# va416xx register map
Vendor: VORAGO TECHNOLOGIES; Series: M4; File version: 1.3
CPU: CM4 r0p1, little endian, no MPU, FPU, 4 interrupt priority bits
Registers are 32-bit, read-write, reset 0x0 unless marked. A register's access mark holds for its fields unless they carry their own. Offsets are from the block's base; [hi:lo] are bit positions; {n}, {i} and the like mark numbered series; 'fields as' and 'values as' point back to an identical list.

## ETH — Ethernet Block
Base 0x40004000
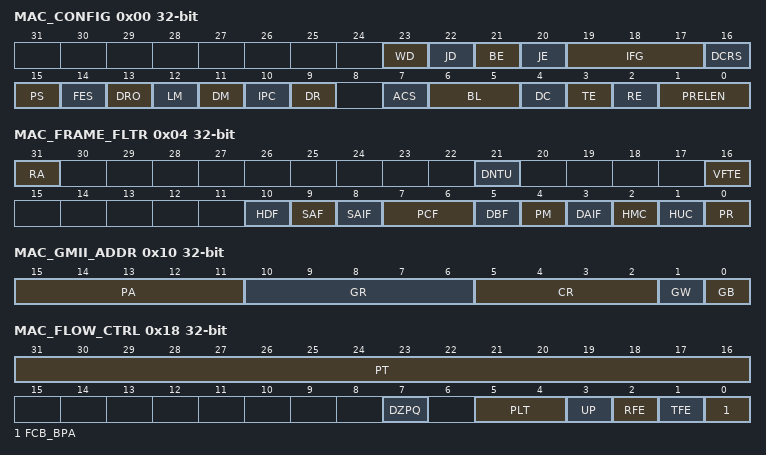
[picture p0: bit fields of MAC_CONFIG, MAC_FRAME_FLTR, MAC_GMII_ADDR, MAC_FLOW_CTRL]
0x00 MAC_CONFIG — Operation mode register for the MAC
  [23] WD — Watchdog disable
  [22] JD — Jabber Disable
  [21] BE — Frame Burst Enable
  [20] JE — Jumbo Frame Enable
  [19:17] IFG — Inter-Frame Gap
  [16] DCRS — Disable Carrier Sense During Transmission
  [15] PS — Port Select
  [14] FES — Speed
  [13] DRO — Disable Receive Own
  [12] LM — Loopback Mode
  [11] DM — Duplex Mode
  [10] IPC — Checksum Offload
  [9] DR — Disable Retry
  [7] ACS — Automatic Pad, or CRC Stripping
  [6:5] BL — Back-Off-Limit
  [4] DC — Deferral Check
  [3] TE — Transmitter Enable
  [2] RE — Receiver Enable
  [1:0] PRELEN — Preamble Length for Transmit frames
0x04 MAC_FRAME_FLTR — Contains the frame filtering controls
  [31] RA — Receive All
  [21] DNTU — Drop non TCP/UDP over IP Frames
  [16] VFTE — VLAN Tag Filter Enable
  [10] HDF — Hash or Perfect Filter
  [9] SAF — Source Address Filter Enable
  [8] SAIF — SA Inverse Filtering
  [7:6] PCF — Pass Control Frames
  [5] DBF — Disable Broadcast Frames
  [4] PM — Pass All Multicast
  [3] DAIF — DA Inverse Filtering
  [2] HMC — Hash Multicast
  [1] HUC — Hash Unicast
  [0] PR — Promiscuous Mode
0x10 MAC_GMII_ADDR — Controls the management cycles to an external PHY
  [15:11] PA — Physical Layer Address
  [10:6] GR — GMII Register
  [5:2] CR — CSR Clock Range
  [1] GW — GMII Write/Read
  [0] GB — GMII Busy
0x14 MAC_GMII_DATA — Contains the data to be written to or read from the PHY register
  [15:0] GD — GMII Data
0x18 MAC_FLOW_CTRL — Controls the generation of control frames
  [31:16] PT — Pause time
  [7] DZPQ — Disable Zero-Quanta Pause
  [5:4] PLT — Pause Low Threshold
  [3] UP — Unicast Pause Frame Detect
  [2] RFE — Receive Flow Control Enable
  [1] TFE — Transmit Flow Control Enable
  [0] FCB_BPA — Flow Control Busy or Backpressure Activate
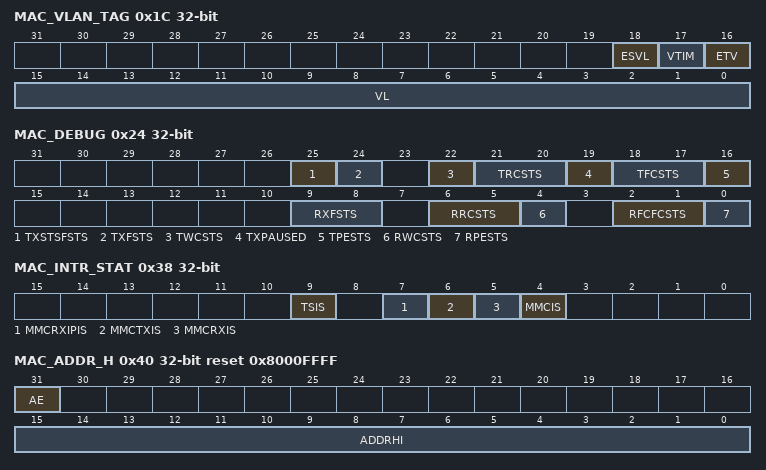
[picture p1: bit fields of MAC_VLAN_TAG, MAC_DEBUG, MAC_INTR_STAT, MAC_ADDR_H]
0x1C MAC_VLAN_TAG — Identifies IEEE 802.1Q VLAN type frames
  [18] ESVL — Enable S-VLAN
  [17] VTIM — VLAN Tag Inverse Match Enable
  [16] ETV — Enable 12-Bit VLAN Tag Comparison
  [15:0] VL — VLAN Tag identifier for Receive Frames
0x24 MAC_DEBUG ro — Gives the status of the various internal blocks for debugging
  [25] TXSTSFSTS — MTL TxStatus FIFO Full Status
  [24] TXFSTS — MTL Tx FIFO Not Empty Status
  [22] TWCSTS — MTL Tx FIFO Write Controller Status
  [21:20] TRCSTS — MTL Tx FIFO Read Controller Status
  [19] TXPAUSED — MAC Transmitter in Pause
  [18:17] TFCSTS — PAC Transmit Frame Controller Status
  [16] TPESTS — MAC GMII or MII Transmit Protocol Engine Status
  [9:8] RXFSTS — MTL RxFIFO Fill-Level Status
  [6:5] RRCSTS — MTL RxFIFO Read Controller State
  [4] RWCSTS — MTL Rx FIFO Write Controller Active Status
  [2:1] RFCFCSTS — MAC Receive Frame FIFO Controller Status
  [0] RPESTS — MAC GMII or MII Receive Protocol Engine Status
0x38 MAC_INTR_STAT ro — Contains the interrupt status
  [9] TSIS — Timestamp Interrupt Status
  [7] MMCRXIPIS — MMC Receive Checksum Offload Interrupt Status
  [6] MMCTXIS — MMC Transmit Interrupt Status
  [5] MMCRXIS — MMC Receive Interrupt Status
  [4] MMCIS — MMC Interrupt Status
0x3C MAC_INTR_MASK — Contains the masks for generating interrupt
  [9] TSIM — Timestamp Interrupt Mask
0x40 MAC_ADDR_H reset 0x8000FFFF — Contains the high 16-bits of the first MAC Address
  [31] AE ro — Address Enable, This bit is always set to 1
  [15:0] ADDRHI ro — MAC Address0[47:32]
0x44 MAC_ADDR_L reset 0xFFFFFFFF — Contains the Low 32-bits of the first MAC Address
  [31:0] ADDRLO ro — MAC Address0[31:0]
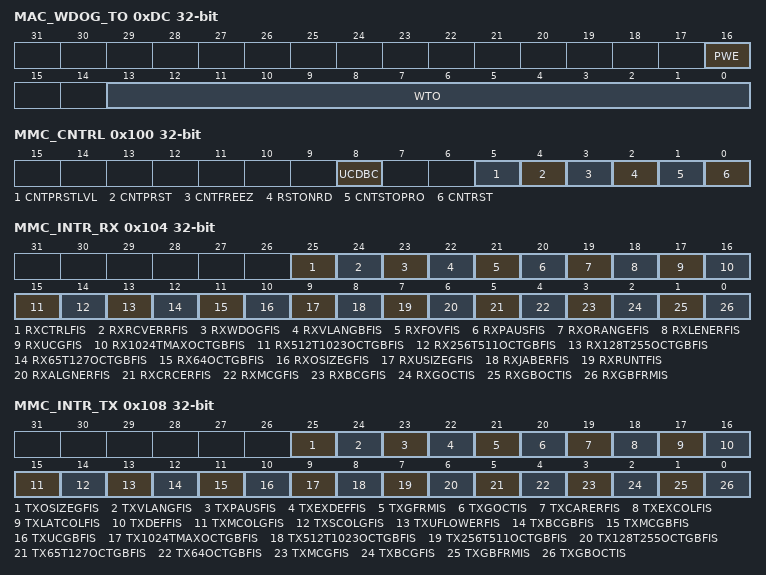
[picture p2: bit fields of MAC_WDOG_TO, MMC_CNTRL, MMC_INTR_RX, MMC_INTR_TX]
0xDC MAC_WDOG_TO — Controls the watchdog time-out for received frames
  [16] PWE — Programmable Watchdog Enable
  [13:0] WTO — Watchdog Timeout
0x100 MMC_CNTRL — MMC Control Register
  [8] UCDBC — Update MMC Counters for Dropped Broadcast Frames
  [5] CNTPRSTLVL — Full-Half Preset
  [4] CNTPRST — Counters Preset
  [3] CNTFREEZ — MMC Counter Freeze
  [2] RSTONRD — Reset on Read
  [1] CNTSTOPRO — Counter Stop Rollover
  [0] CNTRST — Counters Reset
0x104 MMC_INTR_RX — MMC Receive Interrupt Register
  [25] RXCTRLFIS — MMC Receive Control Frame Counter Interrupt Status
  [24] RXRCVERRFIS — MMC Receive Error Frame Counter Interrupt Status
  [23] RXWDOGFIS — MMC Receive Watchdog Error Frame Counter Interrupt Status
  [22] RXVLANGBFIS — MMC Receive VLAN Good Bad Frame Counter Interrupt Status
  [21] RXFOVFIS — MMC Receive FIFO Overflow Frame Counter Interrupt Status
  [20] RXPAUSFIS — MMC Receive Pause Frame Counter Interrupt Status
  [19] RXORANGEFIS — MMC Receive Out Of Range Error Frame Counter Interrupt Status.
  [18] RXLENERFIS — MMC Receive Length Error Frame Counter Interrupt Status
  [17] RXUCGFIS — MMC Receive Unicast Good Frame Counter Interrupt Status
  [16] RX1024TMAXOCTGBFIS — MMC Receive 1024 to Maximum Octet Good Bad Frame Counter Interrupt Status.
  [15] RX512T1023OCTGBFIS — MMC Receive 512 to 1023 Octet Good Bad Frame Counter Interrupt Status
  [14] RX256T511OCTGBFIS — MMC Receive 256 to 511 Octet Good Bad Frame Counter Interrupt Status
  [13] RX128T255OCTGBFIS — MMC Receive 128 to 255 Octet Good Bad Frame Counter Interrupt Status
  [12] RX65T127OCTGBFIS — MMC Receive 65 to 127 Octet Good Bad Frame Counter Interrupt Status
  [11] RX64OCTGBFIS — MMC Receive 64 Octet Good Bad Frame Counter Interrupt Status
  [10] RXOSIZEGFIS — MMC Receive Oversize Good Frame Counter Interrupt Status
  [9] RXUSIZEGFIS — MMC Receive Undersize Good Frame Counter Interrupt Status
  [8] RXJABERFIS — MMC Receive Jabber Error Frame Counter Interrupt Status
  [7] RXRUNTFIS — MMC Receive Runt Frame Counter Interrupt Status
  [6] RXALGNERFIS — MMC Receive Alignment Error Frame Counter Interrupt Status
  [5] RXCRCERFIS — MMC Receive CRC Error Frame Counter Interrupt Status
  [4] RXMCGFIS — MMC Receive Multicast Good Frame Counter Interrupt Status
  [3] RXBCGFIS — MMC Receive Broadcast Good Frame Counter Interrupt Status
  [2] RXGOCTIS — MMC Receive Good Octet Counter Interrupt Status
  [1] RXGBOCTIS — MMC Receive Good Bad Octet Counter Interrupt Status
  [0] RXGBFRMIS — MMC Receive Good Bad Frame Counter Interrupt Status
0x108 MMC_INTR_TX — MMC Transmit Interrupt Register
  [25] TXOSIZEGFIS — MMC Transmit Oversize Good Frame Counter Interrupt Status
  [24] TXVLANGFIS — MMC Transmit VLAN Good Frame Counter Interrupt Status
  [23] TXPAUSFIS — MMC Transmit Pause Frame Counter Interrupt Status
  [22] TXEXDEFFIS — MMC Transmit Excessive Deferral Frame Counter Interrupt Status
  [21] TXGFRMIS — MMC Transmit Good Frame Counter Interrupt Status
  [20] TXGOCTIS — MMC Transmit Good Octet Counter Interrupt Status
  [19] TXCARERFIS — MMC Transmit Carrier Error Frame Counter Interrupt Status
  [18] TXEXCOLFIS — MMC Transmit Excessive Collision Frame Counter Interrupt Status
  [17] TXLATCOLFIS — MMC Transmit Late Collision Frame Counter Interrupt Status
  [16] TXDEFFIS — MMC Transmit Deferred Frame Counter Interrupt Status
  [15] TXMCOLGFIS — MMC Transmit Multiple Collision Good Frame Counter Interrupt Status
  [14] TXSCOLGFIS — MMC Transmit Single Collision Good Frame Counter Interrupt Status
  [13] TXUFLOWERFIS — MMC Transmit Underflow Error Frame Counter Interrupt Status
  [12] TXBCGBFIS — MMC Transmit Broadcast Good Bad Frame Counter Interrupt Status
  [11] TXMCGBFIS — MMC Transmit Multicast Good Bad Frame Counter Interrupt Status
  [10] TXUCGBFIS — MMC Transmit Unicast Good Bad Frame Counter Interrupt Status
  [9] TX1024TMAXOCTGBFIS — MMC Transmit 1024 to Maximum Octet Good Bad Frame Counter
  [8] TX512T1023OCTGBFIS — MMC Transmit 512 to 1023 Octet Good Bad Frame Counter Interrupt Status
  [7] TX256T511OCTGBFIS — MMC Transmit 256 to 511 Octet Good Bad Frame Counter Interrupt Status
  [6] TX128T255OCTGBFIS — MMC Transmit 128 to 255 Octet Good Bad Frame Counter Interrupt Status
  [5] TX65T127OCTGBFIS — MMC Transmit 65 to 127 Octet Good Bad Frame Counter Interrupt Status
  [4] TX64OCTGBFIS — MMC Transmit 64 Octet Good Bad Frame Counter Interrupt Status
  [3] TXMCGFIS — MMC Transmit Multicast Good Frame Counter Interrupt Status
  [2] TXBCGFIS — MMC Transmit Broadcast Good Frame Counter Interrupt Status
  [1] TXGBFRMIS — MMC Transmit Good Bad Frame Counter Interrupt Status
  [0] TXGBOCTIS — MMC Transmit Good Bad Octet Counter Interrupt Status
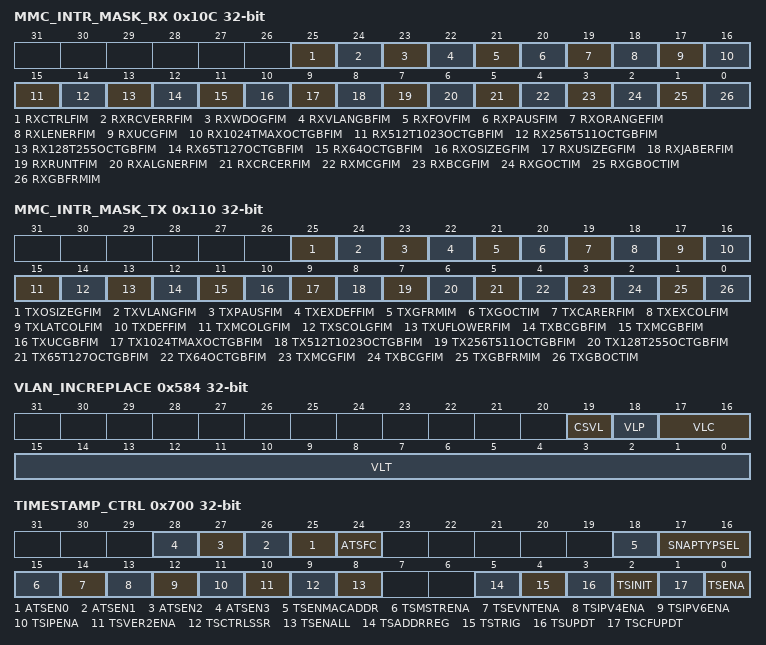
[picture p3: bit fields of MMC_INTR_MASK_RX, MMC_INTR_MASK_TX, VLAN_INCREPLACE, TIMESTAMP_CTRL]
0x10C MMC_INTR_MASK_RX — MMC Receive Interrupt Mask Register
  [25] RXCTRLFIM — MMC Receive Control Frame Counter Interrupt Mask
  [24] RXRCVERRFIM — MMC Receive Error Frame Counter Interrupt Mask
  [23] RXWDOGFIM — MMC Receive Watchdog Error Frame Counter Interrupt Mask
  [22] RXVLANGBFIM — MMC Receive VLAN Good Bad Frame Counter Interrupt Mask
  [21] RXFOVFIM — MMC Receive FIFO Overflow Frame Counter Interrupt Mask
  [20] RXPAUSFIM — MMC Receive Pause Frame Counter Interrupt Mask
  [19] RXORANGEFIM — MMC Receive Out Of Range Error Frame Counter Interrupt Mask
  [18] RXLENERFIM — MMC Receive Length Error Frame Counter Interrupt Mask
  [17] RXUCGFIM — MMC Receive Unicast Good Frame Counter Interrupt Mask
  [16] RX1024TMAXOCTGBFIM — MMC Receive 1024 to Maximum Octet Good Bad Frame Counter Interrupt Mask.
  [15] RX512T1023OCTGBFIM — MMC Receive 512 to 1023 Octet Good Bad Frame Counter Interrupt Mask
  [14] RX256T511OCTGBFIM — MMC Receive 256 to 511 Octet Good Bad Frame Counter Interrupt Mask
  [13] RX128T255OCTGBFIM — MMC Receive 128 to 255 Octet Good Bad Frame Counter Interrupt Mask
  [12] RX65T127OCTGBFIM — MMC Receive 65 to 127 Octet Good Bad Frame Counter Interrupt Mask
  [11] RX64OCTGBFIM — MMC Receive 64 Octet Good Bad Frame Counter Interrupt Mask
  [10] RXOSIZEGFIM — MMC Receive Oversize Good Frame Counter Interrupt Mask
  [9] RXUSIZEGFIM — MMC Receive Undersize Good Frame Counter Interrupt Mask
  [8] RXJABERFIM — MMC Receive Jabber Error Frame Counter Interrupt Mask
  [7] RXRUNTFIM — MMC Receive Runt Frame Counter Interrupt Mask
  [6] RXALGNERFIM — MMC Receive Alignment Error Frame Counter Interrupt Mask
  [5] RXCRCERFIM — MMC Receive CRC Error Frame Counter Interrupt Mask
  [4] RXMCGFIM — MMC Receive Multicast Good Frame Counter Interrupt Mask
  [3] RXBCGFIM — MMC Receive Broadcast Good Frame Counter Interrupt Mask
  [2] RXGOCTIM — MMC Receive Good Octet Counter Interrupt Mask
  [1] RXGBOCTIM — MMC Receive Good Bad Octet Counter Interrupt Mask.
  [0] RXGBFRMIM — MMC Receive Good Bad Frame Counter Interrupt Mask
0x110 MMC_INTR_MASK_TX — MMC Transmit Interrupt Mask Register
  [25] TXOSIZEGFIM — MMC Transmit Oversize Good Frame Counter Interrupt Mask
  [24] TXVLANGFIM — MMC Transmit VLAN Good Frame Counter Interrupt Mask
  [23] TXPAUSFIM — MMC Transmit Pause Frame Counter Interrupt Mask
  [22] TXEXDEFFIM — MMC Transmit Excessive Deferral Frame Counter Interrupt Mask
  [21] TXGFRMIM — MMC Transmit Good Frame Counter Interrupt Mask
  [20] TXGOCTIM — MMC Transmit Good Octet Counter Interrupt Mask
  [19] TXCARERFIM — MMC Transmit Carrier Error Frame Counter Interrupt Mask
  [18] TXEXCOLFIM — MMC Transmit Excessive Collision Frame Counter Interrupt Mask
  [17] TXLATCOLFIM — MMC Transmit Late Collision Frame Counter Interrupt Mask
  [16] TXDEFFIM — MMC Transmit Deferred Frame Counter Interrupt Mask
  [15] TXMCOLGFIM — MMC Transmit Multiple Collision Good Frame Counter Interrupt Mask
  [14] TXSCOLGFIM — MMC Transmit Single Collision Good Frame Counter Interrupt Mask
  [13] TXUFLOWERFIM — MMC Transmit Underflow Error Frame Counter Interrupt Mask
  [12] TXBCGBFIM — MMC Transmit Broadcast Good Bad Frame Counter Interrupt Mask
  [11] TXMCGBFIM — MMC Transmit Multicast Good Bad Frame Counter Interrupt Mask
  [10] TXUCGBFIM — MMC Transmit Unicast Good Bad Frame Counter Interrupt Mask
  [9] TX1024TMAXOCTGBFIM — MMC Transmit 1024 to Maximum Octet Good Bad Frame Counter Interrupt Mask
  [8] TX512T1023OCTGBFIM — MMC Transmit 512 to 1023 Octet Good Bad Frame Counter Interrupt Mask
  [7] TX256T511OCTGBFIM — MC Transmit 256 to 511 Octet Good Bad Frame Counter Interrupt Mask
  [6] TX128T255OCTGBFIM — MMC Transmit 128 to 255 Octet Good Bad Frame Counter Interrupt Mask
  [5] TX65T127OCTGBFIM — MMC Transmit 65 to 127 Octet Good Bad Frame Counter Interrupt Mask
  [4] TX64OCTGBFIM — MMC Transmit 64 Octet Good Bad Frame Counter Interrupt Mask
  [3] TXMCGFIM — MMC Transmit Multicast Good Frame Counter Interrupt Mask
  [2] TXBCGFIM — MMC Transmit Broadcast Good Frame Counter Interrupt Mask
  [1] TXGBFRMIM — MMC Transmit Good Bad Frame Counter Interrupt Mask
  [0] TXGBOCTIM — MMC Transmit Good Bad Octet Counter Interrupt Mask
0x114 TXOCTETCOUNT_GB ro — MMC Transmit Count
  [31:0] COUNT — Number of bytes
0x118 TXFRAMECOUNT_GB ro — MMC Frame Count Register
  [31:0] COUNT — Number of frames
0x11C TXBCASTFRAMES_G ro — MMC Good Broadcast Frames Register
  [31:0] COUNT — Number of frames
0x120 TXMCASTFRAMES_G ro — MMC Good Multicast Frames Register
  [31:0] COUNT — Number of frames
0x124 TX64OCT_GB ro — MMC Good and bad Frames transmitted with length 64
  [31:0] COUNT — Number of frames
0x128 TX65TO127OCT_GB ro — MMC Good and bad Frames transmitted with length 65 to 127
  [31:0] COUNT — Number of frames
0x12C TX128TO255OCT_GB ro — MMC Good and bad Frames transmitted with length 128 to 255
  [31:0] COUNT — Number of frames
0x130 TX256TO511OCT_GB ro — MMC Good and bad Frames transmitted with length 256 to 511
  [31:0] COUNT — Number of frames
0x134 TX512TO1023OCT_GB ro — MMC Good and bad Frames transmitted with length 512 to 1023
  [31:0] COUNT — Number of frames
0x138 TX1024MAXOCT_GB ro — MMC Good and bad Frames transmitted with length 1024 to max bytes
  [31:0] COUNT — Number of frames
0x13C TXUCASTFRAME_GB ro — MMC number of good and bad unicast frames transmitted
  [31:0] COUNT — Number of frames
0x140 TXMCASTFRAME_GB ro — MMC number of good and bad MULTIcast frames transmitted
  [31:0] COUNT — Number of frames
0x144 TXBCASTFRAME_GB ro — MMC number of good and bad broadcast frames transmitted
  [31:0] COUNT — Number of frames
0x148 TXUNDERERR ro — MMC number of frames aborted because of frame underflow error
  [31:0] COUNT — Number of frames
0x14C TXSINGLECOL_G ro — MMC Number of successfully transmitted frames after a single collision
  [31:0] COUNT — Number of frames
0x150 TXMULTICOL_G ro — MMC Number of successfully transmitted frames after multiple collisions
  [31:0] COUNT — Number of frames
0x154 TXDEFERRED ro — MMC Number of successfully transmitted frames after a deferral
  [31:0] COUNT — Number of frames
0x158 TXLATECOL ro — MMC Number of aborted frames because of late collision error
  [31:0] COUNT — Number of frames
0x15C TXEXESSCOL ro — MMC Number of aborted frames because of excessive collision errors
  [31:0] COUNT — Number of frames
0x160 TXCARRIERERROR ro — MMC Number of aborted frames because of carrier sense error
  [31:0] COUNT — Number of frames
0x164 TXOCTETCOUNT_G ro — MMC Number of bytes transmitted frames only in good frames
  [31:0] COUNT — Number of bytes
0x168 TXFRAMECOUNT_G ro — MMC Number of good frames transmitted
  [31:0] COUNT — Number of frames
0x16C TXEXCESSDEF ro — MMC Number of frames aborted because of excessive deferral error
  [31:0] COUNT — Number of frames
0x170 TXPAUSEFRAMES ro — MMC Number of good pause frames transmitted
  [31:0] COUNT — Number of frames
0x174 TXLANFRAMES_G ro — MMC Number of good VLAN frames transmitted
  [31:0] COUNT — Number of frames
0x178 TXOVERSIZE_G ro — MMC Number of frames transmitted without errors
  [31:0] COUNT — Number of frames
0x180 RXFRAMECOUNT_GB ro — MMC Number of good and bad frames received
  [31:0] COUNT — Number of frames
0x184 RXOCTETCOUNT_GB ro — MMC Number of bytes received in good and bad frames
  [31:0] COUNT — Number of bytes
0x188 RXOCTETCOUNT_G ro — MMC Number of bytes received in good frames only
  [31:0] COUNT — Number of bytes
0x18C RXBCASTFRAMES_G ro — MMC Number of good broadcast frames received
  [31:0] COUNT — Number of frames
0x190 RXMCASTFRAMES_G ro — MMC Number of good multicast frames received
  [31:0] COUNT — Number of frames
0x194 RXCRCERROR ro — MMC Number of frames received with CRC error
  [31:0] COUNT — Number of frames
0x198 RXALIGNERROR ro — MMC Number of frames received with alignment error
  [31:0] COUNT — Number of frames
0x19C RXRUNTERROR ro — MMC Number of frames received with runt error
  [31:0] COUNT — Number of frames
0x1A0 RXJABBERERROR ro — MMC Number of giant frames received with length greater than 1518 bytes and with CRC error
  [31:0] COUNT — Number of frames
0x1A4 RXUNDERSIZE_G ro — MMC Number of frames received with length less than 64 bytes
  [31:0] COUNT — Number of frames
0x1A8 RXOVERSIZE_G ro — MMC Number of frames received without errors with length greater than the max size
  [31:0] COUNT — Number of frames
0x1AC RX64OCTETS_GB ro — MMC Number of good and bad frames received with length 64 bytes
  [31:0] COUNT — Number of frames
0x1B0 RX65TO127OCT_GB ro — MMC Number of good and bad frames received with length between 65 and 127 bytes
  [31:0] COUNT — Number of frames
0x1B4 RX128TO255OCT_GB ro — MMC Number of good and bad frames received with length between 128 and 255 bytes
  [31:0] COUNT — Number of frames
0x1B8 RX256TO511OCT_GB ro — MMC Number of good and bad frames received with length between 256 and 511 bytes
  [31:0] COUNT — Number of frames
0x1BC RX512TO1023OCT_GB ro — MMC Number of good and bad frames received with length between 512 and 1023 bytes
  [31:0] COUNT — Number of frames
0x1C0 RX1024MAXOCT_GB ro — MMC Number of good and bad frames received with length between 1024 and max size bytes
  [31:0] COUNT — Number of frames
0x1C4 RXUCASTFRAMES_G ro — MMC Number of received good unicast frames
  [31:0] COUNT — Number of frames
0x1C8 RXLENGTHERROR ro — MMC Number of frames received with length error
  [31:0] COUNT — Number of frames
0x1CC RXOUTRANGETYPE ro — MMC Number of frames received with length field not equal to the valid frame size
  [31:0] COUNT — Number of frames
0x1D0 RXPAUSEFRAMES ro — MMC Number of good and valid Pause frames received
  [31:0] COUNT — Number of frames
0x1D4 RXFIFOOVERFLOW ro — MMC Number of missed received frames because of FIFO overflow
  [31:0] COUNT — Number of frames
0x1D8 RXVLANFRAMES_GB ro — MMC Number of good and bad VLAN frames received
  [31:0] COUNT — Number of frames
0x1DC RXWDOGERROR ro — MMC Number of frames received with error because of watchdog timeout error
  [31:0] COUNT — Number of frames
0x1E0 RXRCVERROR ro — MMC Number of frames received with Receive error or Frame Extension error
  [31:0] COUNT — Number of frames
0x1E4 RXCTRLFRAMES_G ro — MMC Number of received good control frames
  [31:0] COUNT — Number of frames
0x584 VLAN_INCREPLACE — Holds the VLAN Tag for insertion into or replacement in the transmit frames
  [19] CSVL — C-VLAN or S-VLAN
  [18] VLP — VLAN Priority Control
  [17:16] VLC — VLAN Tag Control in Transmit Frames
  [15:0] VLT — VLAN Tag for Transmit Frames
0x588 VLAN_HASHTABLE — Holds the VLAN Hash Table
  [15:0] VLHT — VLAN Hash Table
0x700 TIMESTAMP_CTRL — Controls the IEEE 1588 timestamp generation and update logic
  [n+25] ATSEN{n} (n=0..3) — Auxiliary Snapshot {n} Enable
  [24] ATSFC — Auxiliary Snapshot FIFO Clear
  [18] TSENMACADDR — Enable MAC address for PTP Frame Filtering
  [17:16] SNAPTYPSEL — Select PTP packets for Taking Snapshots
  [15] TSMSTRENA — Enable Snapshot for Messages Relevant to Master
  [14] TSEVNTENA — Enable Timestamp Snapshot for Event Messages
  [13] TSIPV4ENA — Enable Processing of PTP Frames Sent over IPv4-UDP
  [12] TSIPV6ENA — Enable Processing of PTP Frames Sent over IPv6-UDP
  [11] TSIPENA — Enable Processing of PTP over Ethernet Frames
  [10] TSVER2ENA — Enable PTP packet Processing for Version 2 Format
  [9] TSCTRLSSR — Timestamp Digital or Binary Rollover Control
  [8] TSENALL — Enable Timestamp for All Frames
  [5] TSADDRREG — Addend Reg Update
  [4] TSTRIG — Timestamp Interrupt Trigger Enable
  [3] TSUPDT — Timestamp Update
  [2] TSINIT — Timestamp Initialize
  [1] TSCFUPDT — Timestamp Fine or Coarse Update
  [0] TSENA — Timestamp Enable
0x704 SUBSEC_INC — Holds the 8-bit value by which the Sub-Second register is incremented
  [7:0] SSINC — Sub-Second Increment Valuee
0x708 SYSTIME_SECONDS ro — Holds the lower 32 bits of the second field of the system time
  [31:0] TSS — Timestamp Second
0x70C SYSTIME_NANOSEC ro — Holds 32 bits of the nano-second field of the system time
  [30:0] TSSS — Timestamp Sub Seconds
0x710 SYSTIME_SECSUPDAT — Holds the lower 32 bits of the second field to be written to, added to, or subtracted from the system time value
  [31:0] TSS — Timestamp Second
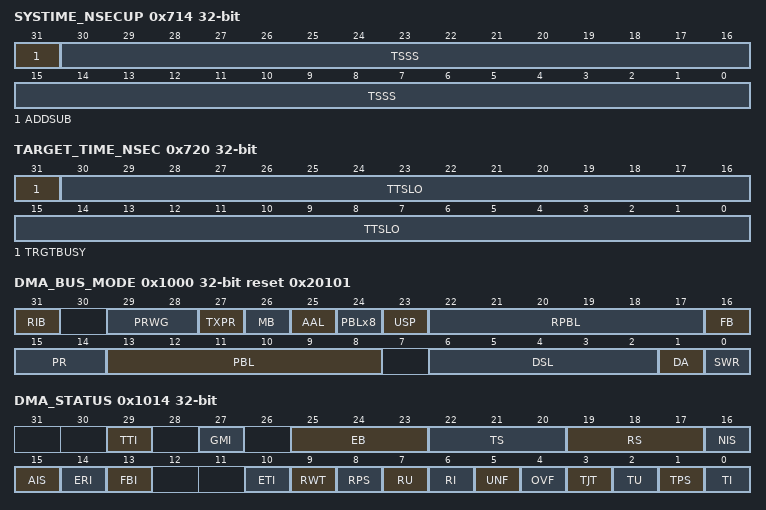
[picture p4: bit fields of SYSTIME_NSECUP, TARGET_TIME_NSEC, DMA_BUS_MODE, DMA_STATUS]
0x714 SYSTIME_NSECUP — Holds 32 bits of the nano-second field to be written to, added to, or subtracted from the system time value
  [31] ADDSUB — Add or Subtract Time
  [30:0] TSSS — Timestamp Sub Seconds
0x718 TIMESTAMPADDEND — This register is used by software to re-adjust the clock frequency linearly to match the Master clock frequency
  [31:0] TSAR — Timestamp Addend Register
0x71C TARGET_TIME_SECS — Holds the high 32-bits of time to be compared with the system time
  [31:0] TSTR — Target Time Seconds Registe
0x720 TARGET_TIME_NSEC — Holds the lower 32-bits of time to be compared with the system time
  [31] TRGTBUSY — 32 Bits of Hash Table
  [30:0] TTSLO — Target Timestamp Low Register
0x1000 DMA_BUS_MODE reset 0x20101 — Controls the DMA Host Interface Mode
  [31] RIB — Rebuild INCRx Burst
  [29:28] PRWG — Channel Priority Weights
  [27] TXPR — Transmit Priority
  [26] MB — Mixed Burst
  [25] AAL — Address-Aligned Beats
  [24] PBLx8 — PBLx8 Mode
  [23] USP — Use Separate PBL
  [22:17] RPBL — Rx DMA PBL
  [16] FB — Fixed Burste
  [15:14] PR — Priority Ratio
  [13:8] PBL — Programmable Burst Lengthe
  [6:2] DSL — Descriptor Skip Length
  [1] DA — DMA Arbitration Scheme
  [0] SWR — Software Reset (Read, Write Set, and Self Clear)
0x1004 DMA_TX_POLL_DEMAND — Used by the host to instruct the DMA to poll the transmit Descriptor list
  [31:0] TPD — Transmit Poll Demand (Read Only and Write Trigger)
0x1008 DMA_RX_POLL_DEMAND — Used by the host to instruct the DMA to poll the Receive Descriptor list
  [31:0] RPD — Receive Poll Demand (Read Only and Write Trigger)
0x100C DMA_RX_DESC_LIST_ADDR — Points the DMA to the start of the Receive Descriptor list
  [31:0] RDESLA — Start of Receive List
0x1010 DMA_TX_DESC_LIST_ADDR — Points the DMA to the start of the Transmit Descriptor list
  [31:0] TDESLA — Start of Transmit List
0x1014 DMA_STATUS ro — Used to determine the status of the DMA
  [29] TTI — Timestamp Trigger Interrupt
  [27] GMI — GMAC MMC Interrupt
  [25:23] EB — Error Bits
  [22:20] TS — Transmit Process State
  [19:17] RS — Receive Process State
  [16] NIS — Normal Interrupt Summary
  [15] AIS — Abnormal Interrupt Summary
  [14] ERI — Early Receive Interrupt
  [13] FBI — Fatal Bus Error Interruptble
  [10] ETI — Early Transmit Interrupt
  [9] RWT — Receive Watchdog Timeout
  [8] RPS — Receive Process Stopped
  [7] RU — Receive Buffer Unavailable
  [6] RI — Receive Interrupt
  [5] UNF — Transmit Underflow
  [4] OVF — Receive Underflow
  [3] TJT — Transmit Jabber Timeout
  [2] TU — Transmit Buffer Unavailable
  [1] TPS — Transmit Process Stopped
  [0] TI — Transmit Interrupt
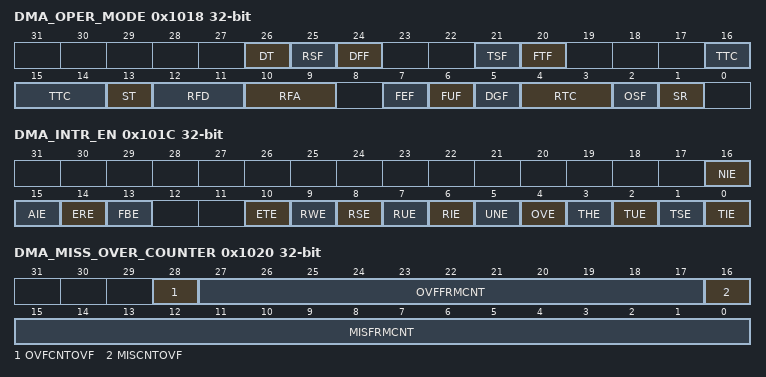
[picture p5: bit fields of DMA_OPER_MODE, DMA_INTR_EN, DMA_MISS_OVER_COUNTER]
0x1018 DMA_OPER_MODE — Sets the Receive and Transmit operation mode and command
  [26] DT — Disable Dropping of TCP/IP Checksum Error Frames
  [25] RSF — Receive Store and Forward
  [24] DFF — Disable Flushing of Received Frames
  [21] TSF — Transmit Store and Forward
  [20] FTF — Flush Transmit FIFO
  [16:14] TTC — Transmit Threshold Control
  [13] ST — Start or Stop Transmission Command
  [12:11] RFD — Threshold for Deactivating Flow Control
  [10:9] RFA — Threshold for Activating Flow Control
  [7] FEF — Forward Error Frames
  [6] FUF — Forward Undersized Good Frames
  [5] DGF — Drop Giant Frames
  [4:3] RTC — Receive Threshold Control
  [2] OSF — Operate on Second Frame
  [1] SR — Start or Stop Receive
0x101C DMA_INTR_EN — Enables the interrupts reported in the status register
  [16] NIE — Normal Interrupt Summary Enable
  [15] AIE — Abnormal Interrupt Summary Enable
  [14] ERE — Early Receive Interrupt Enable
  [13] FBE — Fatal Bus Error Enable
  [10] ETE — Early Transmit Interrupt Enable
  [9] RWE — Receive Watchdog Timeout Enable
  [8] RSE — Receive Stopped Enable
  [7] RUE — Receive Buffer Unavailable Enable
  [6] RIE — Receive Interrupt Enable
  [5] UNE — Underflow Interrupt Enable
  [4] OVE — Overflow Interrupt Enable
  [3] THE — Transmit Jabber Timeout Enable
  [2] TUE — Transmit Buffer Unavailable Enable
  [1] TSE — Transmit Stopped Enable
  [0] TIE — Transmit Interrupt Enable
0x1020 DMA_MISS_OVER_COUNTER — Contains the counters for discarded frames because no Receive Descriptor is available
  [28] OVFCNTOVF — This bit is set every time the Overflow Frame Counter (Bits[27:17])overflows
  [27:17] OVFFRMCNT — This field indicates the number of frames missed by the application
  [16] MISCNTOVF — This bit is set every time Missed Frame Counter (Bits[15:0]) overflows
  [15:0] MISFRMCNT — This field indicates the number of frames missed by the controller because of the Host Receive Buffer being unavailable.
0x1024 DMA_RX_INTR_WDOG_TIMER — Watchdog timeout for Receive Interrupt from DMA
  [7:0] RIWT — These bits indicate the number of system clock cycles x 256 for which the watchdog timer is set.
0x102C DMA_AHB_STATUS — Provides the active status of the read and write channels of the AHB master interface
  [0] AHBMASTRSTS — When high, indicates that the AHB master interface FSMs are in the non-idle state
0x1048 DMA_CURR_TX_DESC — Contains the start address of the current Transmit Descriptor read by the DMA
  [31:0] CURTDESAPTR — Cleared on Reset. Pointer updated by the DMA during operation.
0x104C DMA_CURR_RX_DESC — Contains the start address of the current Receive Descriptor read by the DMA
  [31:0] CURRDESAPTR — Cleared on Reset. Pointer updated by the DMA during operation.
0x1050 DMA_CURR_TX_BUFR_ADDR — Contains the start address of the current Receive Descriptor read by the DMA
  [31:0] CURTBUFAPTR — Cleared on Reset. Pointer updated by the DMA during operation.
0x1054 DMA_CURR_RX_BUFR_ADDR — Contains the current Receive Buffer address read by the DMA
  fields as DMA_CURR_TX_BUFR_ADDR
